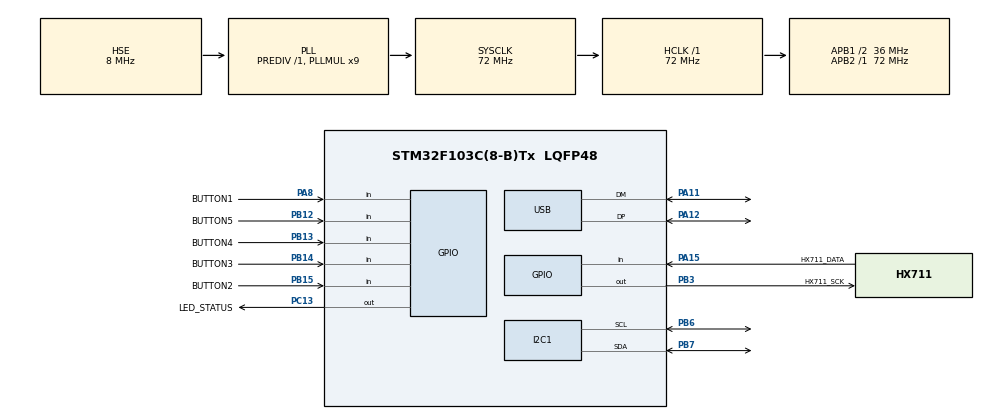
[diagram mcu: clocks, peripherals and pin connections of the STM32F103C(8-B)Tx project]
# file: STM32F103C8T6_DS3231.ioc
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Dma.I2C1_RX.0.Direction=DMA_PERIPH_TO_MEMORY
Dma.I2C1_RX.0.Instance=DMA1_Channel7
Dma.I2C1_RX.0.MemDataAlignment=DMA_MDATAALIGN_BYTE
Dma.I2C1_RX.0.MemInc=DMA_MINC_ENABLE
Dma.I2C1_RX.0.Mode=DMA_CIRCULAR
Dma.I2C1_RX.0.PeriphDataAlignment=DMA_PDATAALIGN_BYTE
Dma.I2C1_RX.0.PeriphInc=DMA_PINC_DISABLE
Dma.I2C1_RX.0.Priority=DMA_PRIORITY_LOW
Dma.Request0=I2C1_RX
I2C1.I2C_Mode=I2C_Fast
Mcu.Family=STM32F1
Mcu.Name=STM32F103C(8-B)Tx
Mcu.Package=LQFP48
NVIC.DMA1_Channel7_IRQn=true\:0\:0\:false\:false\:true
NVIC.I2C1_EV_IRQn=true\:0\:0\:false\:false\:true
NVIC.PriorityGroup=NVIC_PRIORITYGROUP_4
NVIC.USB_LP_CAN1_RX0_IRQn=true\:0\:0\:false\:false\:true
PA11.Mode=Device
PA11.Signal=USB_DM
PA12.Mode=Device
PA12.Signal=USB_DP
PA13.Mode=Serial_Wire
PA13.Signal=SYS_JTMS-SWDIO
PA14.Mode=Serial_Wire
PA14.Signal=SYS_JTCK-SWCLK
PA15.GPIO_Label=HX711_DATA
PA15.GPIO_PuPd=GPIO_PULLUP
PA15.Signal=GPIO_Input
PA8.GPIO_Label=BUTTON1
PA8.Signal=GPIO_Input
PB12.GPIO_Label=BUTTON5
PB12.Signal=GPIO_Input
PB13.GPIO_Label=BUTTON4
PB13.Signal=GPIO_Input
PB14.GPIO_Label=BUTTON3
PB14.Signal=GPIO_Input
PB15.GPIO_Label=BUTTON2
PB15.Signal=GPIO_Input
PB3.GPIO_Label=HX711_SCK
PB3.GPIO_Speed=GPIO_SPEED_FREQ_HIGH
PB3.Signal=GPIO_Output
PB6.Mode=I2C
PB6.Signal=I2C1_SCL
PB7.Mode=I2C
PB7.Signal=I2C1_SDA
PC13-TAMPER-RTC.GPIO_Label=LED_STATUS
PC13-TAMPER-RTC.Signal=GPIO_Output
PC14-OSC32_IN.Mode=LSE-External-Oscillator
PC14-OSC32_IN.Signal=RCC_OSC32_IN
PC15-OSC32_OUT.Mode=LSE-External-Oscillator
PC15-OSC32_OUT.Signal=RCC_OSC32_OUT
PD0-OSC_IN.Mode=HSE-External-Oscillator
PD0-OSC_IN.Signal=RCC_OSC_IN
PD1-OSC_OUT.Mode=HSE-External-Oscillator
PD1-OSC_OUT.Signal=RCC_OSC_OUT
ProjectManager.HeapSize=0x200
ProjectManager.StackSize=0x400
ProjectManager.TargetToolchain=MDK-ARM V5
RCC.AHBFreq_Value=72000000
RCC.APB1CLKDivider=RCC_HCLK_DIV2
RCC.APB1Freq_Value=36000000
RCC.APB1TimFreq_Value=72000000
RCC.APB2Freq_Value=72000000
RCC.APB2TimFreq_Value=72000000
RCC.HCLKFreq_Value=72000000
RCC.PLLMUL=RCC_PLL_MUL9
RCC.SYSCLKFreq_VALUE=72000000
RCC.SYSCLKSource=RCC_SYSCLKSOURCE_PLLCLK
RCC.USBFreq_Value=48000000
RCC.USBPrescaler=RCC_USBCLKSOURCE_PLL_DIV1_5
USB.ep0_mps=DEP0CTL_MPS_16
USB_DEVICE.CLASS_NAME_FS=CUSTOMHID
USB_DEVICE.PRODUCT_STRING_CUSTOMHID_FS=Can kem dien tu.
USB_DEVICE.VirtualMode=CustomHid
USB_DEVICE.VirtualModeFS=Custom_Hid_FS
VP_FATFS_VS_Generic.Mode=User_defined
VP_USB_DEVICE_VS_USB_DEVICE_CUSTOM_HID_FS.Mode=CUSTOM_HID_FS
board=STM32F103C8T6_DS3231

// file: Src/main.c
/**
  ******************************************************************************
  * File Name          : main.c
  * Description        : Main program body
  ******************************************************************************
  * This notice applies to any and all portions of this file
  * that are not between comment pairs USER CODE BEGIN and
  * USER CODE END. Other portions of this file, whether
  * inserted by the user or by software development tools
  * are owned by their respective copyright owners.
  *
  * Copyright (c) 2018 STMicroelectronics International N.V.
  * All rights reserved.
  *
  * Redistribution and use in source and binary forms, with or without
  * modification, are permitted, provided that the following conditions are met:
  *
  * 1. Redistribution of source code must retain the above copyright notice,
  *    this list of conditions and the following disclaimer.
  * 2. Redistributions in binary form must reproduce the above copyright notice,
  *    this list of conditions and the following disclaimer in the documentation
  *    and/or other materials provided with the distribution.
  * 3. Neither the name of STMicroelectronics nor the names of other
  *    contributors to this software may be used to endorse or promote products
  *    derived from this software without specific written permission.
  * 4. This software, including modifications and/or derivative works of this
  *    software, must execute solely and exclusively on microcontroller or
  *    microprocessor devices manufactured by or for STMicroelectronics.
  * 5. Redistribution and use of this software other than as permitted under
  *    this license is void and will automatically terminate your rights under
  *    this license.
  *
  * THIS SOFTWARE IS PROVIDED BY STMICROELECTRONICS AND CONTRIBUTORS "AS IS"
  * AND ANY EXPRESS, IMPLIED OR STATUTORY WARRANTIES, INCLUDING, BUT NOT
  * LIMITED TO, THE IMPLIED WARRANTIES OF MERCHANTABILITY, FITNESS FOR A
  * PARTICULAR PURPOSE AND NON-INFRINGEMENT OF THIRD PARTY INTELLECTUAL PROPERTY
  * RIGHTS ARE DISCLAIMED TO THE FULLEST EXTENT PERMITTED BY LAW. IN NO EVENT
  * SHALL STMICROELECTRONICS OR CONTRIBUTORS BE LIABLE FOR ANY DIRECT, INDIRECT,
  * INCIDENTAL, SPECIAL, EXEMPLARY, OR CONSEQUENTIAL DAMAGES (INCLUDING, BUT NOT
  * LIMITED TO, PROCUREMENT OF SUBSTITUTE GOODS OR SERVICES; LOSS OF USE, DATA,
  * OR PROFITS; OR BUSINESS INTERRUPTION) HOWEVER CAUSED AND ON ANY THEORY OF
  * LIABILITY, WHETHER IN CONTRACT, STRICT LIABILITY, OR TORT (INCLUDING
  * NEGLIGENCE OR OTHERWISE) ARISING IN ANY WAY OUT OF THE USE OF THIS SOFTWARE,
  * EVEN IF ADVISED OF THE POSSIBILITY OF SUCH DAMAGE.
  *
  ******************************************************************************
  */
#include "main.h"
#include "stm32f1xx_hal.h"
#include "fatfs.h"
#include "usb_device.h"

/* USER CODE BEGIN Includes */
#define DS3231_ADD 0x68
/* USER CODE END Includes */

I2C_HandleTypeDef hi2c1;
DMA_HandleTypeDef hdma_i2c1_rx;

/* USER CODE BEGIN PV */
uint8_t receive_Data[7];
uint8_t send_Data[7]; //thoi gian cai dat xuong cho ds3231
uint8_t Second,Minute,Hour,Day,Date,Month,Year;
volatile uint8_t DS3231_Complete=0;
/* Private variables ---------------------------------------------------------*/

/* USER CODE END PV */

void SystemClock_Config(void);
static void MX_GPIO_Init(void);
static void MX_DMA_Init(void);
static void MX_I2C1_Init(void);

/* USER CODE BEGIN PFP */
/* Private function prototypes -----------------------------------------------*/
uint8_t BCD2DEC(uint8_t BCD_NUMBER);
uint8_t DEC2BCD(uint8_t DEC_NUMBER);
/* USER CODE END PFP */

int main(void)
{

  /* MCU Configuration----------------------------------------------------------*/

  /* Reset of all peripherals, Initializes the Flash interface and the Systick. */
  HAL_Init();

  /* Configure the system clock */
  SystemClock_Config();

  /* Initialize all configured peripherals */
  MX_GPIO_Init();
  MX_DMA_Init();
  MX_USB_DEVICE_Init();
  MX_I2C1_Init();
  MX_FATFS_Init();

  /* Infinite loop */
  /* USER CODE BEGIN WHILE */
	HAL_I2C_Mem_Read_DMA(&hi2c1,DS3231_ADD<<1,0,I2C_MEMADD_SIZE_8BIT,receive_Data,7);
  while (1)
  {

	if(DS3231_Complete){HAL_I2C_Mem_Read_DMA(&hi2c1,DS3231_ADD<<1,0,I2C_MEMADD_SIZE_8BIT,receive_Data,7);DS3231_Complete=0;}

  /* USER CODE END WHILE */

  }

}

/** Hàm chuyển đổi giá trị BCD sang số thập phân (DEC)
*/
uint8_t BCD2DEC(uint8_t BCD_NUMBER)
{
	return (BCD_NUMBER>>4)*10+(BCD_NUMBER&0xf);
}
/** Hàm chuyển đổi giá trị thập phân sang số BCD
***DEC_NUMBER số <100
*/

uint8_t DEC2BCD(uint8_t DEC_NUMBER)
{
	return (DEC_NUMBER/10)<<4|(DEC_NUMBER%10);
}
//hàm xử lý ngắt DMA của I2C đọc về.
void HAL_I2C_MemRxCpltCallback(I2C_HandleTypeDef *hi2c)
{
	if(hi2c->Instance==hi2c1.Instance)
	{
		Second=BCD2DEC(receive_Data[0]);
		Minute=BCD2DEC(receive_Data[1]);
		Hour=BCD2DEC(receive_Data[2]);
		Day=BCD2DEC(receive_Data[3]);
		Date=BCD2DEC(receive_Data[4]);
		Month=BCD2DEC(receive_Data[5]);
		Year=BCD2DEC(receive_Data[6]);
		DS3231_Complete=1;
	}

}
/** System Clock Configuration
*/
void SystemClock_Config(void)
{

  RCC_OscInitTypeDef RCC_OscInitStruct;
  RCC_ClkInitTypeDef RCC_ClkInitStruct;
  RCC_PeriphCLKInitTypeDef PeriphClkInit;

    /**Initializes the CPU, AHB and APB busses clocks
    */
  RCC_OscInitStruct.OscillatorType = RCC_OSCILLATORTYPE_HSE;
  RCC_OscInitStruct.HSEState = RCC_HSE_ON;
  RCC_OscInitStruct.HSEPredivValue = RCC_HSE_PREDIV_DIV1;
  RCC_OscInitStruct.HSIState = RCC_HSI_ON;
  RCC_OscInitStruct.PLL.PLLState = RCC_PLL_ON;
  RCC_OscInitStruct.PLL.PLLSource = RCC_PLLSOURCE_HSE;
  RCC_OscInitStruct.PLL.PLLMUL = RCC_PLL_MUL9;
  if (HAL_RCC_OscConfig(&RCC_OscInitStruct) != HAL_OK)
  {
    _Error_Handler(__FILE__, __LINE__);
  }

    /**Initializes the CPU, AHB and APB busses clocks
    */
  RCC_ClkInitStruct.ClockType = RCC_CLOCKTYPE_HCLK|RCC_CLOCKTYPE_SYSCLK
                              |RCC_CLOCKTYPE_PCLK1|RCC_CLOCKTYPE_PCLK2;
  RCC_ClkInitStruct.SYSCLKSource = RCC_SYSCLKSOURCE_PLLCLK;
  RCC_ClkInitStruct.AHBCLKDivider = RCC_SYSCLK_DIV1;
  RCC_ClkInitStruct.APB1CLKDivider = RCC_HCLK_DIV2;
  RCC_ClkInitStruct.APB2CLKDivider = RCC_HCLK_DIV1;

  if (HAL_RCC_ClockConfig(&RCC_ClkInitStruct, FLASH_LATENCY_2) != HAL_OK)
  {
    _Error_Handler(__FILE__, __LINE__);
  }

  PeriphClkInit.PeriphClockSelection = RCC_PERIPHCLK_USB;
  PeriphClkInit.UsbClockSelection = RCC_USBCLKSOURCE_PLL_DIV1_5;
  if (HAL_RCCEx_PeriphCLKConfig(&PeriphClkInit) != HAL_OK)
  {
    _Error_Handler(__FILE__, __LINE__);
  }

    /**Configure the Systick interrupt time
    */
  HAL_SYSTICK_Config(HAL_RCC_GetHCLKFreq()/1000);

    /**Configure the Systick
    */
  HAL_SYSTICK_CLKSourceConfig(SYSTICK_CLKSOURCE_HCLK);

  /* SysTick_IRQn interrupt configuration */
  HAL_NVIC_SetPriority(SysTick_IRQn, 0, 0);
}

/* I2C1 init function */
static void MX_I2C1_Init(void)
{

  hi2c1.Instance = I2C1;
  hi2c1.Init.ClockSpeed = 400000;
  hi2c1.Init.DutyCycle = I2C_DUTYCYCLE_2;
  hi2c1.Init.OwnAddress1 = 0;
  hi2c1.Init.AddressingMode = I2C_ADDRESSINGMODE_7BIT;
  hi2c1.Init.DualAddressMode = I2C_DUALADDRESS_DISABLE;
  hi2c1.Init.OwnAddress2 = 0;
  hi2c1.Init.GeneralCallMode = I2C_GENERALCALL_DISABLE;
  hi2c1.Init.NoStretchMode = I2C_NOSTRETCH_DISABLE;
  if (HAL_I2C_Init(&hi2c1) != HAL_OK)
  {
    _Error_Handler(__FILE__, __LINE__);
  }

}

static void MX_DMA_Init(void)
{
  /* DMA controller clock enable */
  __HAL_RCC_DMA1_CLK_ENABLE();

  /* DMA interrupt init */
  /* DMA1_Channel7_IRQn interrupt configuration */
  HAL_NVIC_SetPriority(DMA1_Channel7_IRQn, 0, 0);
  HAL_NVIC_EnableIRQ(DMA1_Channel7_IRQn);

}

/** Configure pins as
        * Analog
        * Input
        * Output
        * EVENT_OUT
        * EXTI
*/
static void MX_GPIO_Init(void)
{

  GPIO_InitTypeDef GPIO_InitStruct;

  /* GPIO Ports Clock Enable */
  __HAL_RCC_GPIOC_CLK_ENABLE();
  __HAL_RCC_GPIOD_CLK_ENABLE();
  __HAL_RCC_GPIOB_CLK_ENABLE();
  __HAL_RCC_GPIOA_CLK_ENABLE();

  /*Configure GPIO pin Output Level */
  HAL_GPIO_WritePin(LED_STATUS_GPIO_Port, LED_STATUS_Pin, GPIO_PIN_RESET);

  /*Configure GPIO pin Output Level */
  HAL_GPIO_WritePin(HX711_SCK_GPIO_Port, HX711_SCK_Pin, GPIO_PIN_RESET);

  /*Configure GPIO pin : LED_STATUS_Pin */
  GPIO_InitStruct.Pin = LED_STATUS_Pin;
  GPIO_InitStruct.Mode = GPIO_MODE_OUTPUT_PP;
  GPIO_InitStruct.Speed = GPIO_SPEED_FREQ_LOW;
  HAL_GPIO_Init(LED_STATUS_GPIO_Port, &GPIO_InitStruct);

  /*Configure GPIO pins : BUTTON5_Pin BUTTON4_Pin BUTTON3_Pin BUTTON2_Pin */
  GPIO_InitStruct.Pin = BUTTON5_Pin|BUTTON4_Pin|BUTTON3_Pin|BUTTON2_Pin;
  GPIO_InitStruct.Mode = GPIO_MODE_INPUT;
  GPIO_InitStruct.Pull = GPIO_NOPULL;
  HAL_GPIO_Init(GPIOB, &GPIO_InitStruct);

  /*Configure GPIO pin : BUTTON1_Pin */
  GPIO_InitStruct.Pin = BUTTON1_Pin;
  GPIO_InitStruct.Mode = GPIO_MODE_INPUT;
  GPIO_InitStruct.Pull = GPIO_NOPULL;
  HAL_GPIO_Init(BUTTON1_GPIO_Port, &GPIO_InitStruct);

  /*Configure GPIO pin : HX711_DATA_Pin */
  GPIO_InitStruct.Pin = HX711_DATA_Pin;
  GPIO_InitStruct.Mode = GPIO_MODE_INPUT;
  GPIO_InitStruct.Pull = GPIO_PULLUP;
  HAL_GPIO_Init(HX711_DATA_GPIO_Port, &GPIO_InitStruct);

  /*Configure GPIO pin : HX711_SCK_Pin */
  GPIO_InitStruct.Pin = HX711_SCK_Pin;
  GPIO_InitStruct.Mode = GPIO_MODE_OUTPUT_PP;
  GPIO_InitStruct.Speed = GPIO_SPEED_FREQ_HIGH;
  HAL_GPIO_Init(HX711_SCK_GPIO_Port, &GPIO_InitStruct);

}

void _Error_Handler(char * file, int line)
{
  while(1)
  {
  }
}

/************************ (C) COPYRIGHT STMicroelectronics *****END OF FILE****/
